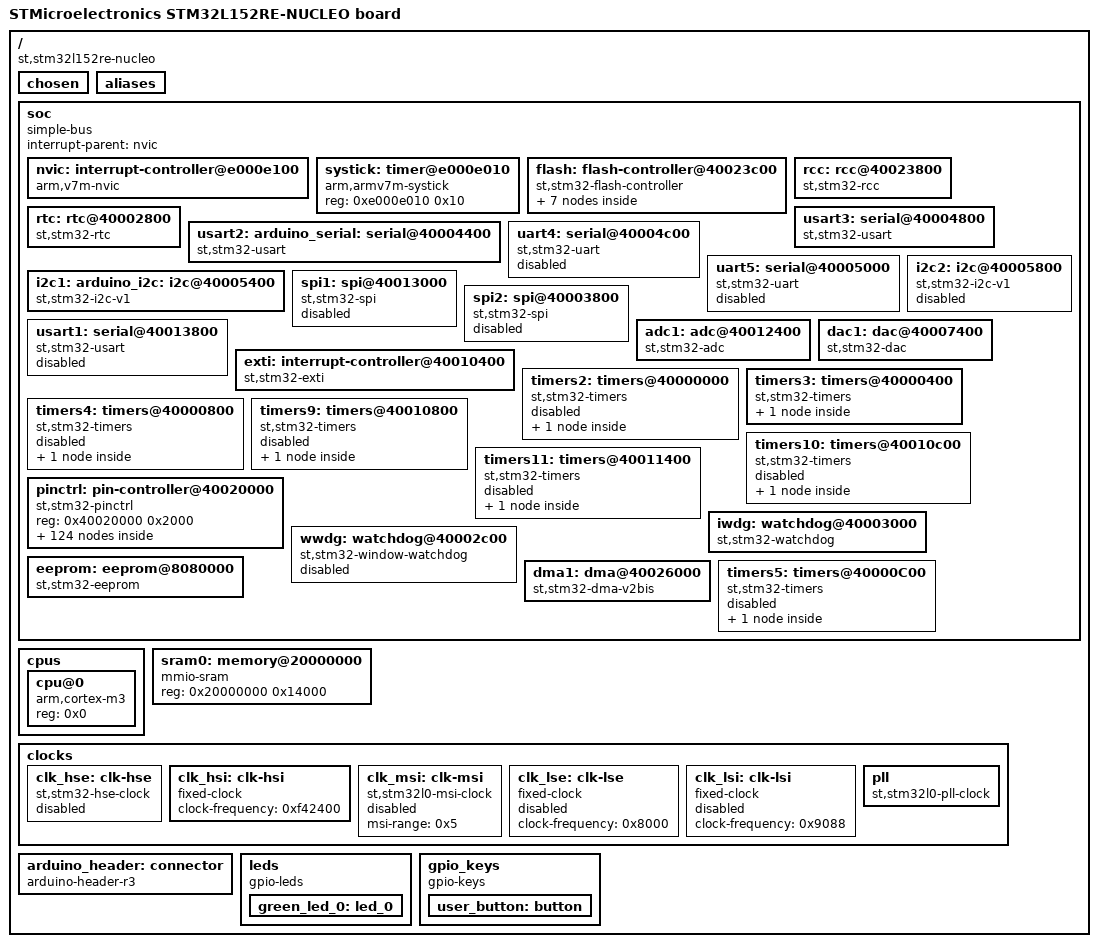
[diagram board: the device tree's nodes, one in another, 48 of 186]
/dts-v1/;

/ {
	#address-cells = < 0x1 >;
	#size-cells = < 0x1 >;
	model = "STMicroelectronics STM32L152RE-NUCLEO board";
	compatible = "st,stm32l152re-nucleo";
	chosen {
		zephyr,flash-controller = &flash;
		zephyr,console = &usart2;
		zephyr,shell-uart = &usart2;
		zephyr,sram = &sram0;
		zephyr,flash = &flash0;
		zephyr,code-partition = &slot0_partition;
	};
	aliases {
		led0 = &green_led_0;
		sw0 = &user_button;
		eeprom-0 = &eeprom;
	};
	soc {
		#address-cells = < 0x1 >;
		#size-cells = < 0x1 >;
		compatible = "simple-bus";
		interrupt-parent = < &nvic >;
		ranges;
		nvic: interrupt-controller@e000e100 {
			#address-cells = < 0x1 >;
			compatible = "arm,v7m-nvic";
			reg = < 0xe000e100 0xc00 >;
			interrupt-controller;
			#interrupt-cells = < 0x2 >;
			arm,num-irq-priority-bits = < 0x4 >;
			phandle = < 0x1 >;
		};
		systick: timer@e000e010 {
			compatible = "arm,armv7m-systick";
			reg = < 0xe000e010 0x10 >;
		};
		flash: flash-controller@40023c00 {
			compatible = "st,stm32-flash-controller", "st,stm32l1-flash-controller";
			label = "FLASH_CTRL";
			reg = < 0x40023c00 0x400 >;
			interrupts = < 0x4 0x0 >;
			clocks = < &rcc 0x0 0x8000 >;
			#address-cells = < 0x1 >;
			#size-cells = < 0x1 >;
			flash0: flash@8000000 {
				compatible = "st,stm32-nv-flash", "soc-nv-flash";
				label = "FLASH_STM32";
				write-block-size = < 0x4 >;
				max-erase-time = < 0x4 >;
				reg = < 0x8000000 0x80000 >;
				partitions {
					compatible = "fixed-partitions";
					#address-cells = < 0x1 >;
					#size-cells = < 0x1 >;
					storage_partition: partition@7f800 {
						label = "storage";
						reg = < 0x7f800 0x800 >;
					};
					boot_partitions: partition@0 {
						label = "mcuboot";
						reg = < 0x0 0xc000 >;
					};
					slot0_partition: partition@c000 {
						label = "image-0";
						reg = < 0xc000 0x5c000 >;
					};
					slot1_partition: partition@68000 {
						label = "image-1";
						reg = < 0x680000 0x5c000 >;
					};
					scratch_partition: partition@c4000 {
						label = "image-scratch";
						reg = < 0xc4000 0x4000 >;
					};
				};
			};
		};
		rcc: rcc@40023800 {
			compatible = "st,stm32-rcc";
			#clock-cells = < 0x2 >;
			reg = < 0x40023800 0x400 >;
			clocks = < &pll >;
			clock-frequency = < 0x1e84800 >;
			ahb-prescaler = < 0x1 >;
			apb1-prescaler = < 0x1 >;
			apb2-prescaler = < 0x1 >;
			phandle = < 0x2 >;
		};
		rtc: rtc@40002800 {
			compatible = "st,stm32-rtc";
			reg = < 0x40002800 0x400 >;
			interrupts = < 0x29 0x0 >;
			clocks = < &rcc 0x2 0x10000000 >;
			prescaler = < 0x8000 >;
			status = "okay";
			label = "RTC_0";
		};
		usart2: arduino_serial: serial@40004400 {
			compatible = "st,stm32-usart", "st,stm32-uart";
			reg = < 0x40004400 0x400 >;
			clocks = < &rcc 0x2 0x20000 >;
			interrupts = < 0x26 0x0 >;
			status = "okay";
			label = "UART_2";
			pinctrl-0 = < &usart2_tx_pa2 &usart2_rx_pa3 >;
			current-speed = < 0x1c200 >;
		};
		usart3: serial@40004800 {
			compatible = "st,stm32-usart", "st,stm32-uart";
			reg = < 0x40004800 0x400 >;
			clocks = < &rcc 0x2 0x40000 >;
			interrupts = < 0x27 0x0 >;
			status = "okay";
			label = "UART_3";
			pinctrl-0 = < &usart3_tx_pb10 &usart3_rx_pb11 >;
			current-speed = < 0x1c200 >;
			dmas = < &dma1 0x2 0x20440 >, < &dma1 0x3 0x20480 >;
			dma-names = "tx", "rx";
		};
		uart4: serial@40004c00 {
			compatible = "st,stm32-uart";
			reg = < 0x40004c00 0x400 >;
			clocks = < &rcc 0x2 0x80000 >;
			interrupts = < 0x30 0x0 >;
			status = "disabled";
			label = "UART_4";
		};
		uart5: serial@40005000 {
			compatible = "st,stm32-uart";
			reg = < 0x40005000 0x400 >;
			clocks = < &rcc 0x2 0x100000 >;
			interrupts = < 0x31 0x0 >;
			status = "disabled";
			label = "UART_5";
		};
		i2c1: arduino_i2c: i2c@40005400 {
			compatible = "st,stm32-i2c-v1";
			clock-frequency = < 0x186a0 >;
			#address-cells = < 0x1 >;
			#size-cells = < 0x0 >;
			reg = < 0x40005400 0x400 >;
			clocks = < &rcc 0x2 0x200000 >;
			interrupts = < 0x1f 0x0 >, < 0x20 0x0 >;
			interrupt-names = "event", "error";
			status = "okay";
			label = "I2C_1";
			pinctrl-0 = < &i2c1_scl_pb8 &i2c1_sda_pb9 >;
		};
		i2c2: i2c@40005800 {
			compatible = "st,stm32-i2c-v1";
			clock-frequency = < 0x186a0 >;
			#address-cells = < 0x1 >;
			#size-cells = < 0x0 >;
			reg = < 0x40005800 0x400 >;
			clocks = < &rcc 0x2 0x400000 >;
			interrupts = < 0x21 0x0 >, < 0x22 0x0 >;
			interrupt-names = "event", "error";
			status = "disabled";
			label = "I2C_2";
		};
		spi1: spi@40013000 {
			compatible = "st,stm32-spi";
			#address-cells = < 0x1 >;
			#size-cells = < 0x0 >;
			reg = < 0x40013000 0x400 >;
			clocks = < &rcc 0x3 0x1000 >;
			interrupts = < 0x23 0x0 >;
			status = "disabled";
			label = "SPI_1";
		};
		spi2: spi@40003800 {
			compatible = "st,stm32-spi";
			#address-cells = < 0x1 >;
			#size-cells = < 0x0 >;
			reg = < 0x40003800 0x400 >;
			clocks = < &rcc 0x2 0x4000 >;
			interrupts = < 0x24 0x0 >;
			status = "disabled";
			label = "SPI_2";
		};
		usart1: serial@40013800 {
			compatible = "st,stm32-usart", "st,stm32-uart";
			reg = < 0x40013800 0x400 >;
			clocks = < &rcc 0x3 0x4000 >;
			interrupts = < 0x25 0x0 >;
			status = "disabled";
			label = "UART_1";
		};
		adc1: adc@40012400 {
			compatible = "st,stm32-adc";
			reg = < 0x40012400 0x400 >;
			clocks = < &rcc 0x3 0x200 >;
			interrupts = < 0x12 0x0 >;
			status = "okay";
			label = "ADC_1";
			#io-channel-cells = < 0x1 >;
			pinctrl-0 = < &adc_in0_pa0 >;
		};
		dac1: dac@40007400 {
			compatible = "st,stm32-dac";
			reg = < 0x40007400 0x400 >;
			clocks = < &rcc 0x2 0x20000000 >;
			status = "okay";
			label = "DAC_1";
			#io-channel-cells = < 0x1 >;
			pinctrl-0 = < &dac_out1_pa4 >;
		};
		exti: interrupt-controller@40010400 {
			compatible = "st,stm32-exti";
			interrupt-controller;
			#interrupt-cells = < 0x1 >;
			reg = < 0x40010400 0x400 >;
		};
		timers2: timers@40000000 {
			compatible = "st,stm32-timers";
			reg = < 0x40000000 0x400 >;
			clocks = < &rcc 0x2 0x1 >;
			interrupts = < 0x1c 0x0 >;
			interrupt-names = "global";
			status = "disabled";
			label = "TIMERS_2";
			pwm {
				compatible = "st,stm32-pwm";
				status = "disabled";
				st,prescaler = < 0x0 >;
				label = "PWM_2";
				#pwm-cells = < 0x3 >;
			};
		};
		timers3: timers@40000400 {
			compatible = "st,stm32-timers";
			reg = < 0x40000400 0x400 >;
			clocks = < &rcc 0x2 0x2 >;
			interrupts = < 0x1d 0x0 >;
			interrupt-names = "global";
			status = "okay";
			label = "TIMERS_3";
			pwm3: pwm {
				compatible = "st,stm32-pwm";
				status = "okay";
				st,prescaler = < 0x0 >;
				label = "PWM_3";
				#pwm-cells = < 0x3 >;
				pinctrl-0 = < &tim3_ch1_pa6 >;
			};
		};
		timers4: timers@40000800 {
			compatible = "st,stm32-timers";
			reg = < 0x40000800 0x400 >;
			clocks = < &rcc 0x2 0x4 >;
			interrupts = < 0x1e 0x0 >;
			interrupt-names = "global";
			status = "disabled";
			label = "TIMERS_4";
			pwm {
				compatible = "st,stm32-pwm";
				status = "disabled";
				st,prescaler = < 0x0 >;
				label = "PWM_4";
				#pwm-cells = < 0x3 >;
			};
		};
		timers9: timers@40010800 {
			compatible = "st,stm32-timers";
			reg = < 0x40010800 0x400 >;
			clocks = < &rcc 0x3 0x4 >;
			interrupts = < 0x19 0x0 >;
			interrupt-names = "global";
			status = "disabled";
			label = "TIMERS_9";
			pwm {
				compatible = "st,stm32-pwm";
				status = "disabled";
				st,prescaler = < 0x0 >;
				label = "PWM_9";
				#pwm-cells = < 0x3 >;
			};
		};
		timers10: timers@40010c00 {
			compatible = "st,stm32-timers";
			reg = < 0x40010c00 0x400 >;
			clocks = < &rcc 0x3 0x8 >;
			interrupts = < 0x1a 0x0 >;
			interrupt-names = "global";
			status = "disabled";
			label = "TIMERS_10";
			pwm {
				compatible = "st,stm32-pwm";
				status = "disabled";
				st,prescaler = < 0x0 >;
				label = "PWM_10";
				#pwm-cells = < 0x3 >;
			};
		};
		timers11: timers@40011400 {
			compatible = "st,stm32-timers";
			reg = < 0x40011400 0x400 >;
			clocks = < &rcc 0x3 0x10 >;
			interrupts = < 0x1b 0x0 >;
			interrupt-names = "global";
			status = "disabled";
			label = "TIMERS_11";
			pwm {
				compatible = "st,stm32-pwm";
				status = "disabled";
				st,prescaler = < 0x0 >;
				label = "PWM_11";
				#pwm-cells = < 0x3 >;
			};
		};
		pinctrl: pin-controller@40020000 {
			compatible = "st,stm32-pinctrl";
			#address-cells = < 0x1 >;
			#size-cells = < 0x1 >;
			reg = < 0x40020000 0x2000 >;
			gpioa: gpio@40020000 {
				compatible = "st,stm32-gpio";
				gpio-controller;
				#gpio-cells = < 0x2 >;
				reg = < 0x40020000 0x400 >;
				clocks = < &rcc 0x0 0x1 >;
				label = "GPIOA";
				phandle = < 0xf >;
			};
			gpiob: gpio@40020400 {
				compatible = "st,stm32-gpio";
				gpio-controller;
				#gpio-cells = < 0x2 >;
				reg = < 0x40020400 0x400 >;
				clocks = < &rcc 0x0 0x2 >;
				label = "GPIOB";
				phandle = < 0x10 >;
			};
			gpioc: gpio@40020800 {
				compatible = "st,stm32-gpio";
				gpio-controller;
				#gpio-cells = < 0x2 >;
				reg = < 0x40020800 0x400 >;
				clocks = < &rcc 0x0 0x4 >;
				label = "GPIOC";
				phandle = < 0x11 >;
			};
			gpiod: gpio@40020c00 {
				compatible = "st,stm32-gpio";
				gpio-controller;
				#gpio-cells = < 0x2 >;
				reg = < 0x40020c00 0x400 >;
				clocks = < &rcc 0x0 0x8 >;
				label = "GPIOD";
			};
			gpioe: gpio@40021000 {
				compatible = "st,stm32-gpio";
				gpio-controller;
				#gpio-cells = < 0x2 >;
				reg = < 0x40021000 0x400 >;
				clocks = < &rcc 0x0 0x10 >;
				label = "GPIOE";
			};
			gpioh: gpio@40021400 {
				compatible = "st,stm32-gpio";
				gpio-controller;
				#gpio-cells = < 0x2 >;
				reg = < 0x40021400 0x400 >;
				clocks = < &rcc 0x0 0x20 >;
				label = "GPIOH";
			};
			adc_in0_pa0: adc_in0_pa0 {
				pinmux = < 0x10 >;
				phandle = < 0xb >;
			};
			adc_in1_pa1: adc_in1_pa1 {
				pinmux = < 0x110 >;
			};
			adc_in2_pa2: adc_in2_pa2 {
				pinmux = < 0x210 >;
			};
			adc_in3_pa3: adc_in3_pa3 {
				pinmux = < 0x310 >;
			};
			adc_in4_pa4: adc_in4_pa4 {
				pinmux = < 0x410 >;
			};
			adc_in5_pa5: adc_in5_pa5 {
				pinmux = < 0x510 >;
			};
			adc_in6_pa6: adc_in6_pa6 {
				pinmux = < 0x610 >;
			};
			adc_in7_pa7: adc_in7_pa7 {
				pinmux = < 0x710 >;
			};
			adc_in8_pb0: adc_in8_pb0 {
				pinmux = < 0x1010 >;
			};
			adc_in9_pb1: adc_in9_pb1 {
				pinmux = < 0x1110 >;
			};
			adc_in18_pb12: adc_in18_pb12 {
				pinmux = < 0x1c10 >;
			};
			adc_in19_pb13: adc_in19_pb13 {
				pinmux = < 0x1d10 >;
			};
			adc_in20_pb14: adc_in20_pb14 {
				pinmux = < 0x1e10 >;
			};
			adc_in21_pb15: adc_in21_pb15 {
				pinmux = < 0x1f10 >;
			};
			adc_in10_pc0: adc_in10_pc0 {
				pinmux = < 0x2010 >;
			};
			adc_in11_pc1: adc_in11_pc1 {
				pinmux = < 0x2110 >;
			};
			adc_in12_pc2: adc_in12_pc2 {
				pinmux = < 0x2210 >;
			};
			adc_in13_pc3: adc_in13_pc3 {
				pinmux = < 0x2310 >;
			};
			adc_in14_pc4: adc_in14_pc4 {
				pinmux = < 0x2410 >;
			};
			adc_in15_pc5: adc_in15_pc5 {
				pinmux = < 0x2510 >;
			};
			dac_out1_pa4: dac_out1_pa4 {
				pinmux = < 0x410 >;
				phandle = < 0xc >;
			};
			dac_out2_pa5: dac_out2_pa5 {
				pinmux = < 0x510 >;
			};
			i2c1_scl_pb6: i2c1_scl_pb6 {
				pinmux = < 0x1604 >;
				bias-pull-up;
				drive-open-drain;
			};
			i2c1_scl_pb8: i2c1_scl_pb8 {
				pinmux = < 0x1804 >;
				bias-pull-up;
				drive-open-drain;
				phandle = < 0x9 >;
			};
			i2c2_scl_pb10: i2c2_scl_pb10 {
				pinmux = < 0x1a04 >;
				bias-pull-up;
				drive-open-drain;
			};
			i2c1_sda_pb7: i2c1_sda_pb7 {
				pinmux = < 0x1704 >;
				bias-pull-up;
				drive-open-drain;
			};
			i2c1_sda_pb9: i2c1_sda_pb9 {
				pinmux = < 0x1904 >;
				bias-pull-up;
				drive-open-drain;
				phandle = < 0xa >;
			};
			i2c2_sda_pb11: i2c2_sda_pb11 {
				pinmux = < 0x1b04 >;
				bias-pull-up;
				drive-open-drain;
			};
			i2s2_ck_pb13: i2s2_ck_pb13 {
				pinmux = < 0x1d05 >;
				slew-rate = "very-high-speed";
			};
			i2s3_ck_pb3: i2s3_ck_pb3 {
				pinmux = < 0x1306 >;
				slew-rate = "very-high-speed";
			};
			i2s3_ck_pc10: i2s3_ck_pc10 {
				pinmux = < 0x2a06 >;
				slew-rate = "very-high-speed";
			};
			i2s2_sd_pb15: i2s2_sd_pb15 {
				pinmux = < 0x1f05 >;
			};
			i2s3_sd_pb5: i2s3_sd_pb5 {
				pinmux = < 0x1506 >;
			};
			i2s3_sd_pc12: i2s3_sd_pc12 {
				pinmux = < 0x2c06 >;
			};
			i2s2_ws_pb12: i2s2_ws_pb12 {
				pinmux = < 0x1c05 >;
			};
			i2s3_ws_pa4: i2s3_ws_pa4 {
				pinmux = < 0x406 >;
			};
			i2s3_ws_pa15: i2s3_ws_pa15 {
				pinmux = < 0xf06 >;
			};
			spi1_miso_pa6: spi1_miso_pa6 {
				pinmux = < 0x605 >;
				bias-pull-down;
			};
			spi1_miso_pa11: spi1_miso_pa11 {
				pinmux = < 0xb05 >;
				bias-pull-down;
			};
			spi1_miso_pb4: spi1_miso_pb4 {
				pinmux = < 0x1405 >;
				bias-pull-down;
			};
			spi2_miso_pb14: spi2_miso_pb14 {
				pinmux = < 0x1e05 >;
				bias-pull-down;
			};
			spi3_miso_pb4: spi3_miso_pb4 {
				pinmux = < 0x1406 >;
				bias-pull-down;
			};
			spi3_miso_pc11: spi3_miso_pc11 {
				pinmux = < 0x2b06 >;
				bias-pull-down;
			};
			spi1_mosi_pa7: spi1_mosi_pa7 {
				pinmux = < 0x705 >;
				bias-pull-down;
			};
			spi1_mosi_pa12: spi1_mosi_pa12 {
				pinmux = < 0xc05 >;
				bias-pull-down;
			};
			spi1_mosi_pb5: spi1_mosi_pb5 {
				pinmux = < 0x1505 >;
				bias-pull-down;
			};
			spi2_mosi_pb15: spi2_mosi_pb15 {
				pinmux = < 0x1f05 >;
				bias-pull-down;
			};
			spi3_mosi_pb5: spi3_mosi_pb5 {
				pinmux = < 0x1506 >;
				bias-pull-down;
			};
			spi3_mosi_pc12: spi3_mosi_pc12 {
				pinmux = < 0x2c06 >;
				bias-pull-down;
			};
			spi1_nss_pa4: spi1_nss_pa4 {
				pinmux = < 0x405 >;
				bias-pull-up;
			};
			spi1_nss_pa15: spi1_nss_pa15 {
				pinmux = < 0xf05 >;
				bias-pull-up;
			};
			spi2_nss_pb12: spi2_nss_pb12 {
				pinmux = < 0x1c05 >;
				bias-pull-up;
			};
			spi3_nss_pa4: spi3_nss_pa4 {
				pinmux = < 0x406 >;
				bias-pull-up;
			};
			spi3_nss_pa15: spi3_nss_pa15 {
				pinmux = < 0xf06 >;
				bias-pull-up;
			};
			spi1_sck_pa5: spi1_sck_pa5 {
				pinmux = < 0x505 >;
				bias-pull-down;
				slew-rate = "very-high-speed";
			};
			spi1_sck_pb3: spi1_sck_pb3 {
				pinmux = < 0x1305 >;
				bias-pull-down;
				slew-rate = "very-high-speed";
			};
			spi2_sck_pb13: spi2_sck_pb13 {
				pinmux = < 0x1d05 >;
				bias-pull-down;
				slew-rate = "very-high-speed";
			};
			spi3_sck_pb3: spi3_sck_pb3 {
				pinmux = < 0x1306 >;
				bias-pull-down;
				slew-rate = "very-high-speed";
			};
			spi3_sck_pc10: spi3_sck_pc10 {
				pinmux = < 0x2a06 >;
				bias-pull-down;
				slew-rate = "very-high-speed";
			};
			tim10_ch1_pa6: tim10_ch1_pa6 {
				pinmux = < 0x603 >;
			};
			tim10_ch1_pb8: tim10_ch1_pb8 {
				pinmux = < 0x1803 >;
			};
			tim10_ch1_pb12: tim10_ch1_pb12 {
				pinmux = < 0x1c03 >;
			};
			tim11_ch1_pa7: tim11_ch1_pa7 {
				pinmux = < 0x703 >;
			};
			tim11_ch1_pb9: tim11_ch1_pb9 {
				pinmux = < 0x1903 >;
			};
			tim11_ch1_pb15: tim11_ch1_pb15 {
				pinmux = < 0x1f03 >;
			};
			tim2_ch1_pa0: tim2_ch1_pa0 {
				pinmux = < 0x1 >;
			};
			tim2_ch2_pa1: tim2_ch2_pa1 {
				pinmux = < 0x101 >;
			};
			tim2_ch3_pa2: tim2_ch3_pa2 {
				pinmux = < 0x201 >;
			};
			tim2_ch4_pa3: tim2_ch4_pa3 {
				pinmux = < 0x301 >;
			};
			tim2_ch1_pa5: tim2_ch1_pa5 {
				pinmux = < 0x501 >;
			};
			tim2_ch1_pa15: tim2_ch1_pa15 {
				pinmux = < 0xf01 >;
			};
			tim2_ch2_pb3: tim2_ch2_pb3 {
				pinmux = < 0x1301 >;
			};
			tim2_ch3_pb10: tim2_ch3_pb10 {
				pinmux = < 0x1a01 >;
			};
			tim2_ch4_pb11: tim2_ch4_pb11 {
				pinmux = < 0x1b01 >;
			};
			tim3_ch1_pa6: tim3_ch1_pa6 {
				pinmux = < 0x602 >;
				phandle = < 0xd >;
			};
			tim3_ch2_pa7: tim3_ch2_pa7 {
				pinmux = < 0x702 >;
			};
			tim3_ch3_pb0: tim3_ch3_pb0 {
				pinmux = < 0x1002 >;
			};
			tim3_ch4_pb1: tim3_ch4_pb1 {
				pinmux = < 0x1102 >;
			};
			tim3_ch1_pb4: tim3_ch1_pb4 {
				pinmux = < 0x1402 >;
			};
			tim3_ch2_pb5: tim3_ch2_pb5 {
				pinmux = < 0x1502 >;
			};
			tim3_ch1_pc6: tim3_ch1_pc6 {
				pinmux = < 0x2602 >;
			};
			tim3_ch2_pc7: tim3_ch2_pc7 {
				pinmux = < 0x2702 >;
			};
			tim3_ch3_pc8: tim3_ch3_pc8 {
				pinmux = < 0x2802 >;
			};
			tim3_ch4_pc9: tim3_ch4_pc9 {
				pinmux = < 0x2902 >;
			};
			tim4_ch1_pb6: tim4_ch1_pb6 {
				pinmux = < 0x1602 >;
			};
			tim4_ch2_pb7: tim4_ch2_pb7 {
				pinmux = < 0x1702 >;
			};
			tim4_ch3_pb8: tim4_ch3_pb8 {
				pinmux = < 0x1802 >;
			};
			tim4_ch4_pb9: tim4_ch4_pb9 {
				pinmux = < 0x1902 >;
			};
			tim5_ch1_pa0: tim5_ch1_pa0 {
				pinmux = < 0x2 >;
			};
			tim5_ch2_pa1: tim5_ch2_pa1 {
				pinmux = < 0x102 >;
			};
			tim5_ch3_pa2: tim5_ch3_pa2 {
				pinmux = < 0x202 >;
			};
			tim5_ch4_pa3: tim5_ch4_pa3 {
				pinmux = < 0x302 >;
			};
			tim9_ch1_pa2: tim9_ch1_pa2 {
				pinmux = < 0x203 >;
			};
			tim9_ch2_pa3: tim9_ch2_pa3 {
				pinmux = < 0x303 >;
			};
			tim9_ch1_pb13: tim9_ch1_pb13 {
				pinmux = < 0x1d03 >;
			};
			tim9_ch2_pb14: tim9_ch2_pb14 {
				pinmux = < 0x1e03 >;
			};
			usart1_cts_pa11: usart1_cts_pa11 {
				pinmux = < 0xb07 >;
				bias-pull-up;
				drive-open-drain;
			};
			usart2_cts_pa0: usart2_cts_pa0 {
				pinmux = < 0x7 >;
				bias-pull-up;
				drive-open-drain;
			};
			usart3_cts_pb13: usart3_cts_pb13 {
				pinmux = < 0x1d07 >;
				bias-pull-up;
				drive-open-drain;
			};
			usart1_rts_pa12: usart1_rts_pa12 {
				pinmux = < 0xc07 >;
				bias-pull-up;
				drive-open-drain;
			};
			usart2_rts_pa1: usart2_rts_pa1 {
				pinmux = < 0x107 >;
				bias-pull-up;
				drive-open-drain;
			};
			usart3_rts_pb14: usart3_rts_pb14 {
				pinmux = < 0x1e07 >;
				bias-pull-up;
				drive-open-drain;
			};
			usart1_rx_pa10: usart1_rx_pa10 {
				pinmux = < 0xa07 >;
			};
			usart1_rx_pb7: usart1_rx_pb7 {
				pinmux = < 0x1707 >;
			};
			usart2_rx_pa3: usart2_rx_pa3 {
				pinmux = < 0x307 >;
				phandle = < 0x5 >;
			};
			usart3_rx_pb11: usart3_rx_pb11 {
				pinmux = < 0x1b07 >;
				phandle = < 0x7 >;
			};
			usart3_rx_pc11: usart3_rx_pc11 {
				pinmux = < 0x2b07 >;
			};
			uart4_rx_pc11: uart4_rx_pc11 {
				pinmux = < 0x2b08 >;
			};
			uart5_rx_pd2: uart5_rx_pd2 {
				pinmux = < 0x3208 >;
			};
			usart1_tx_pa9: usart1_tx_pa9 {
				pinmux = < 0x907 >;
				bias-pull-up;
			};
			usart1_tx_pb6: usart1_tx_pb6 {
				pinmux = < 0x1607 >;
				bias-pull-up;
			};
			usart2_tx_pa2: usart2_tx_pa2 {
				pinmux = < 0x207 >;
				bias-pull-up;
				phandle = < 0x4 >;
			};
			usart3_tx_pb10: usart3_tx_pb10 {
				pinmux = < 0x1a07 >;
				bias-pull-up;
				phandle = < 0x6 >;
			};
			usart3_tx_pc10: usart3_tx_pc10 {
				pinmux = < 0x2a07 >;
				bias-pull-up;
			};
			uart4_tx_pc10: uart4_tx_pc10 {
				pinmux = < 0x2a08 >;
				bias-pull-up;
			};
			uart5_tx_pc12: uart5_tx_pc12 {
				pinmux = < 0x2c08 >;
				bias-pull-up;
			};
			usb_dm_pa11: usb_dm_pa11 {
				pinmux = < 0xb0a >;
			};
			usb_dp_pa12: usb_dp_pa12 {
				pinmux = < 0xc0a >;
			};
		};
		iwdg: watchdog@40003000 {
			compatible = "st,stm32-watchdog";
			reg = < 0x40003000 0x400 >;
			label = "IWDG";
			status = "okay";
		};
		wwdg: watchdog@40002c00 {
			compatible = "st,stm32-window-watchdog";
			reg = < 0x40002c00 0x400 >;
			clocks = < &rcc 0x2 0x800 >;
			interrupts = < 0x0 0x7 >;
			status = "disabled";
			label = "WWDG";
		};
		eeprom: eeprom@8080000 {
			compatible = "st,stm32-eeprom";
			status = "okay";
			label = "EEPROM_0";
			reg = < 0x8080000 0x4000 >;
		};
		dma1: dma@40026000 {
			compatible = "st,stm32-dma-v2bis";
			#dma-cells = < 0x2 >;
			reg = < 0x40026000 0x400 >;
			clocks = < &rcc 0x0 0x1000000 >;
			interrupts = < 0xb 0x0 0xc 0x0 0xd 0x0 0xe 0x0 0xf 0x0 0x10 0x0 0x11 0x0 >;
			status = "okay";
			label = "DMA_1";
			phandle = < 0x8 >;
		};
		timers5: timers@40000C00 {
			compatible = "st,stm32-timers";
			reg = < 0x40000c00 0x400 >;
			clocks = < &rcc 0x2 0x8 >;
			interrupts = < 0x2d 0x0 >;
			interrupt-names = "global";
			status = "disabled";
			label = "TIMERS_5";
			pwm {
				compatible = "st,stm32-pwm";
				status = "disabled";
				st,prescaler = < 0x0 >;
				label = "PWM_5";
				#pwm-cells = < 0x3 >;
			};
		};
	};
	cpus {
		#address-cells = < 0x1 >;
		#size-cells = < 0x0 >;
		cpu@0 {
			device_type = "cpu";
			compatible = "arm,cortex-m3";
			reg = < 0x0 >;
		};
	};
	sram0: memory@20000000 {
		compatible = "mmio-sram";
		reg = < 0x20000000 0x14000 >;
	};
	clocks {
		clk_hse: clk-hse {
			#clock-cells = < 0x0 >;
			compatible = "st,stm32-hse-clock";
			status = "disabled";
		};
		clk_hsi: clk-hsi {
			#clock-cells = < 0x0 >;
			compatible = "fixed-clock";
			clock-frequency = < 0xf42400 >;
			status = "okay";
			phandle = < 0xe >;
		};
		clk_msi: clk-msi {
			#clock-cells = < 0x0 >;
			compatible = "st,stm32l0-msi-clock";
			msi-range = < 0x5 >;
			status = "disabled";
		};
		clk_lse: clk-lse {
			#clock-cells = < 0x0 >;
			compatible = "fixed-clock";
			clock-frequency = < 0x8000 >;
			status = "disabled";
		};
		clk_lsi: clk-lsi {
			#clock-cells = < 0x0 >;
			compatible = "fixed-clock";
			clock-frequency = < 0x9088 >;
			status = "disabled";
		};
		pll: pll {
			#clock-cells = < 0x0 >;
			compatible = "st,stm32l0-pll-clock";
			status = "okay";
			div = < 0x2 >;
			mul = < 0x4 >;
			clocks = < &clk_hsi >;
			phandle = < 0x3 >;
		};
	};
	arduino_header: connector {
		compatible = "arduino-header-r3";
		#gpio-cells = < 0x2 >;
		gpio-map-mask = < 0xffffffff 0xffffffc0 >;
		gpio-map-pass-thru = < 0x0 0x3f >;
		gpio-map = < 0x0 0x0 &gpioa 0x0 0x0 >, < 0x1 0x0 &gpioa 0x1 0x0 >, < 0x2 0x0 &gpioa 0x4 0x0 >, < 0x3 0x0 &gpiob 0x0 0x0 >, < 0x4 0x0 &gpioc 0x1 0x0 >, < 0x5 0x0 &gpioc 0x0 0x0 >, < 0x6 0x0 &gpioa 0x3 0x0 >, < 0x7 0x0 &gpioa 0x2 0x0 >, < 0x8 0x0 &gpioa 0xa 0x0 >, < 0x9 0x0 &gpiob 0x3 0x0 >, < 0xa 0x0 &gpiob 0x5 0x0 >, < 0xb 0x0 &gpiob 0x4 0x0 >, < 0xc 0x0 &gpiob 0xa 0x0 >, < 0xd 0x0 &gpioa 0x8 0x0 >, < 0xe 0x0 &gpioa 0x9 0x0 >, < 0xf 0x0 &gpioc 0x7 0x0 >, < 0x10 0x0 &gpiob 0x6 0x0 >, < 0x11 0x0 &gpioa 0x7 0x0 >, < 0x12 0x0 &gpioa 0x6 0x0 >, < 0x13 0x0 &gpioa 0x5 0x0 >, < 0x14 0x0 &gpiob 0x9 0x0 >, < 0x15 0x0 &gpiob 0x8 0x0 >;
	};
	leds {
		compatible = "gpio-leds";
		green_led_0: led_0 {
			gpios = < &gpioa 0x5 0x1 >;
			label = "User LD2";
		};
	};
	gpio_keys {
		compatible = "gpio-keys";
		user_button: button {
			label = "User";
			gpios = < &gpioc 0xd 0x1 >;
		};
	};
};
